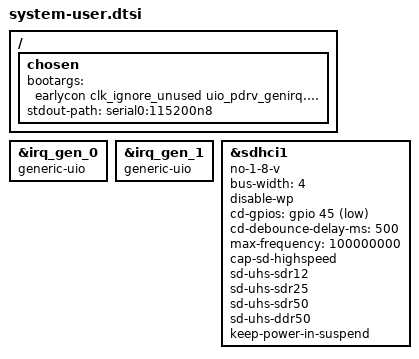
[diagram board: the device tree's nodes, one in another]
/include/ "system-conf.dtsi"
/ {
    chosen {
        bootargs = "earlycon clk_ignore_unused   uio_pdrv_genirq.of_id=generic-uio root=/dev/mmcblk0p2 rw rootwait";
        stdout-path = "serial0:115200n8";
    };
};

&irq_gen_0 {
    compatible = "generic-uio";
};

&irq_gen_1 {
    compatible = "generic-uio";
};

&sdhci1 {
	no-1-8-v;
	bus-width = <4>;
	disable-wp;
	cd-gpios = <&gpio 45 1>;	// cd-gpios = <&gpio 45 GPIO_ACTIVE_LOW>;
	cd-debounce-delay-ms = <500>;
	max-frequency = <100000000>;
	cap-sd-highspeed;
	sd-uhs-sdr12;
	sd-uhs-sdr25;
	sd-uhs-sdr50;
	sd-uhs-ddr50;
	keep-power-in-suspend;
	status = "okay";
};
